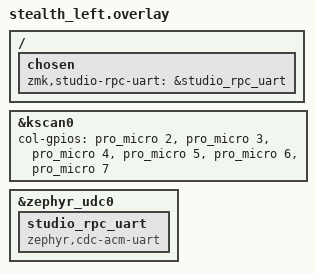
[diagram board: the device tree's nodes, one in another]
/*
 * Copyright (c) 2020 Pete Johanson
 *
 * SPDX-License-Identifier: MIT
 */

#include "stealth.dtsi"

&kscan0 {
    col-gpios = <&pro_micro 2 GPIO_ACTIVE_HIGH>,
                <&pro_micro 3 GPIO_ACTIVE_HIGH>,
                <&pro_micro 4 GPIO_ACTIVE_HIGH>,
                <&pro_micro 5 GPIO_ACTIVE_HIGH>,
                <&pro_micro 6 GPIO_ACTIVE_HIGH>,
                <&pro_micro 7 GPIO_ACTIVE_HIGH>;
};

/ {
    chosen {
        zmk,studio-rpc-uart = &studio_rpc_uart;
    };
};

&zephyr_udc0 {
    studio_rpc_uart: studio_rpc_uart {
        compatible = "zephyr,cdc-acm-uart";
    };
};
